# RN831X_RN861X_MCU register map
File version: v0.0.1
CPU: RN831X_RN861X_MCU r1p0, little endian, MPU, no FPU
Registers are 32-bit, read-write, reset 0x0 unless marked. A register's access mark holds for its fields unless they carry their own. Offsets are from the block's base; [hi:lo] are bit positions; {n}, {i} and the like mark numbered series.

## LCD_CORE0 — LCD Module core0
Base 0x20060000
Same registers: LCD_CORE1 0xA0060000
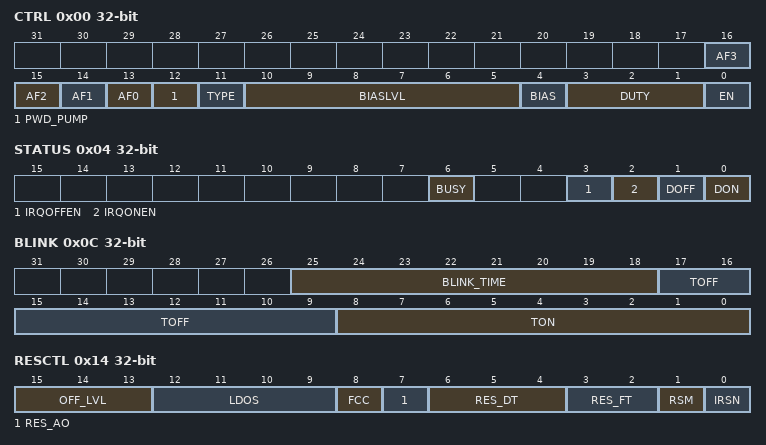
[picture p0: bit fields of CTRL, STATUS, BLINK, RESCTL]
0x00 CTRL — LCD control register
  [n+13] AF{n} (n=0..3) — Alternate funciton of SEG{n} and COM{n+4}
    0=SEG (Select IO as SEG); 1=COM (Select IO as COM)
  [12] PWD_PUMP — LCD charge pump enable bit
    0=EN (LCD PUMP enable); 1=DIS (LCD PUMP disable)
  [11] TYPE — LCD driver wave type bit
    0=A (Select LCD drive type A); 1=B (Select LCD drive type B)
  [10:5] BIASLVL — Charge pump bias level control bit
  [4] BIAS — LCD bias control bit
    0=1_3 (Select LCD bias as 1/3 voltage bias); 1=1_4 (Select LCD bias as 1/4 voltage bias)
  [3:1] DUTY — LCD duty control bit
    0=STA (static output (COM0)); 1=1_2 (duty cycle = 1/2 (COM0~1)); 2=1_3 (duty cycle = 1/3 (COM0~2)); 3=1_4 (duty cycle = 1/4 (COM0~3)); 4=1_6 (duty cycle = 1/6 (COM0~5)); 5=1_8 (duty cycle = 1/8 (COM0~7))
  [0] EN — LCD enable bit
0x04 STATUS access per field — LCD status register
  [6] BUSY ro — LCD busy bit
  [3] IRQOFFEN rw — Display off IRQ enble bit
  [2] IRQONEN rw — Display on IRQ enble bit
  [1] DOFF rw write-1-clears — Display on pending bit
    0=NUL (LCD display off did not occured); 1=OCC (LCD display off occured)
  [0] DON rw write-1-clears — Display off pending bit
    0=NUL (LCD display on did not occured); 1=OCC (LCD display on occured)
0x08 CLKDIV access not given — LCD clock control register
  [7:0] CLKDIV — LCD clock prescale configuration bits
0x0C BLINK — LCD blink register
  [25:18] BLINK_TIME — Display off pending bit
  [17:9] TOFF — Display on pending bit
  [8:0] TON — Display on IRQ enble bit
0x10 PS access not given reset 0xCCC — Pump setup time register
  [15:0] PS — Pump setup time bits
0x14 RESCTL — Resistor control register
  [15:13] OFF_LVL — IO output after disable LCD
    0=V0 (OFF_LVL = 0/6/7 output LCDV0); 1=VA (Output LCDVA); 2=VB (Output LCDVB); 3=VC (Output LCDVC); 4=VD (Output LCDVD); 5=HIGHZ (Output High-Z)
  [12:9] LDOS — LDO output level selection bits
    0=2P7 (Select LDO 2.7V as output level); 1=2P76 (Select LDO 2.76V as output level); 2=2P82 (Select LDO 2.82V as output level); 3=2P88 (Select LDO 2.88V as output level); 4=2P94 (Select LDO 2.94V as output level); 5=3P0 (Select LDO 3.0V as output level); 6=3P06 (Select LDO 3.06V as output level); 7=3P12 (Select LDO 3.12V as output level); 8=3P18 (Select LDO 3.18V as output level); 9=3P24 (Select LDO 3.24V as output level); 10=3P3 (Select LDO 3.3V as output level); 11=3P36 (Select LDO 3.36V as output level); 12=3P42 (Select LDO 3.42V as output level); 13=3P48 (Select LDO 3.48V as output level); 14=3P54 (Select LDO 3.54V as output level); 15=3P6 (Select LDO 3.6V as output level)
  [8] FCC — Fast charging control bit
    0=OFF (Turn off fast charging function); 1=ON (Turn on fast charging function)
  [7] RES_AO — Resistor string time-division driving type configuration bit
    0=TIMEDIV (Resistors time-division driving); 1=ALWAYS (Resistors always drive)
  [6:4] RES_DT — 20k resistor driving time configuration bits
  [3:2] RES_FT — 20k resistor driving count configuration bits
    0=Driving once per cycle; 1=Driving 2 times per cycle; 2=Driving 3 times per cycle; 3=Driving 4 times per cycle
  [1] RSM — Internal resistor division mode signal selection bit
    0=SMALL (20k resistor time-division connected, 200k resistor short circuited); 1=SWITCH (Time-division switching between 20k resistor and 200k resistor)
  [0] IRSN — Resistor division mode selection bit
    0=INTERRES (Internal resistor division mode)
{0x20+i} BUF{i} 8-bit access not given (i=0..35) — LCD buffer{i} register
  [7:0] BUF{i} — Data bits of SEG({i}) COM[7:0]
0x44 BUF36 8-bit access not given — LCD buffer35 register
  [7:0] BUF36 — Data bits of SEG(36) COM[7:0]
0x45 BUF37 8-bit access not given — LCD buffer35 register
  [7:0] BUF37 — Data bits of SEG(37) COM[7:0]
